VERSION "HIPBNYYYYYYYYYYYYYYYYYYYYYYYYYYYYYYYYYYYYY/4/%%%/4/'%**4YYY///"

NS_ :

BS_:

BU_: AX221123

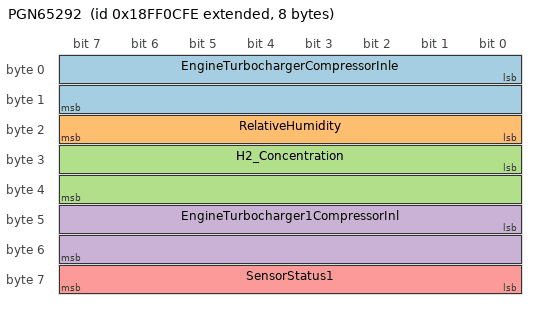
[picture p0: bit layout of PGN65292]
BO_ 2566851838 PGN65292: 8 Vector__XXX
 SG_ EngineTurbochargerCompressorInle : 0|16@1+ (0.0078125,-250) [0|0] "kPa" Vector__XXX
 SG_ RelativeHumidity : 16|8@1+ (0.4,0) [0|0] "%" Vector__XXX
 SG_ H2_Concentration : 24|16@1+ (0.0025,0) [0|0] "% H2" Vector__XXX
 SG_ EngineTurbocharger1CompressorInl : 40|16@1+ (0.03125,-273) [0|0] "degC" Vector__XXX
 SG_ SensorStatus1 : 56|8@1+ (1,0) [0|0] "" Vector__XXX

CM_ "$File: //depot/auto/dbc/Third_party_components/TEDU/Amphenol_TTI_TEDU/0.2.1.0/Amphenol_TTI_TEDU.dbc $
$Change: 215850 $
$DateTime: 2024/08/14 16:39:54 $
$Revision: #1 $";
BA_DEF_  "DBName" STRING ;
BA_DEF_  "BusType" STRING ;
BA_DEF_ BO_  "VFrameFormat" ENUM  "StandardCAN","ExtendedCAN","reserved","J1939PG","reserved","reserved","reserved","reserved","reserved","reserved","reserved","reserved","reserved","reserved","StandardCAN_FD","ExtendedCAN_FD";
BA_DEF_ BO_  "GenMsgCycleTime" INT 0 65535;
BA_DEF_ SG_  "SystemSignalLongSymbol" STRING ;
BA_DEF_DEF_  "BusType" "";
BA_DEF_DEF_  "VFrameFormat" "J1939PG";
BA_DEF_DEF_  "GenMsgCycleTime" 0;
BA_DEF_DEF_  "SystemSignalLongSymbol" "";
BA_DEF_DEF_  "DBName" "Amphenol_TTI_TEDU";
BA_ "BusType" "CAN";
BA_ "GenMsgCycleTime" BO_ 2566851838 100;
BA_ "SystemSignalLongSymbol" SG_ 2566851838 EngineTurbochargerCompressorInle "EngineTurbochargerCompressorInletPressure";
BA_ "SystemSignalLongSymbol" SG_ 2566851838 EngineTurbocharger1CompressorInl "EngineTurbocharger1CompressorInletTemperature";
